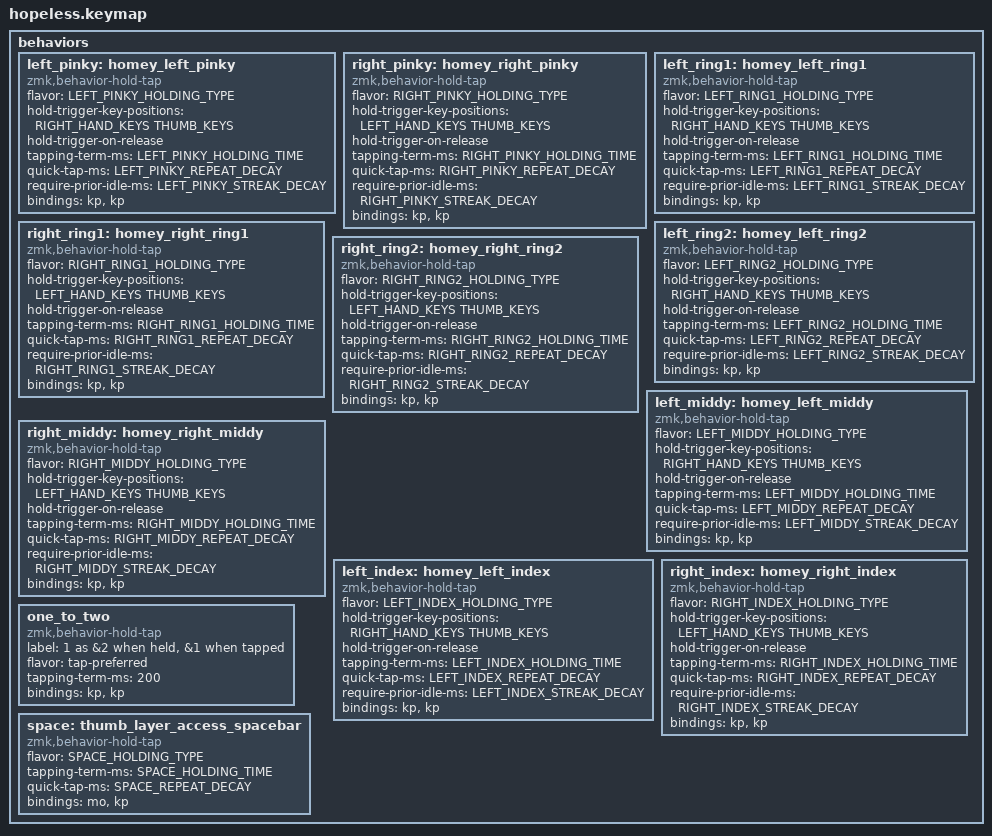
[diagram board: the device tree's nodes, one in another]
// NOTE: Use the `#define` settings below to customize this keymap!
// For example, here are the main optional features you can enable:
#define DIFFICULTY_LEVEL  4 // 0:custom, 1:easy -> 5:hard (see below)
// TIP: Add more setting overrides here instead of editing them below.

//////////////////////////////////////////////////////////////////////////////
//
// Advanced Home Row Mods (HRM) Example based on
// Sunaku's Keymap v35 -- "Glorious Engrammer"
// - https://github.com/sunaku/glove80-keymaps
//
//////////////////////////////////////////////////////////////////////////////

//
// DIFFICULTY_LEVEL specifies your level of expertise with this keymap.
// It's meant to help newcomers gradually work their way up to mastery.
// You can disable this setting by omitting it or assigning a `0` zero.
//
// #define DIFFICULTY_LEVEL 0 // custom (see defaults below)
// #define DIFFICULTY_LEVEL 1 // novice (500ms)
// #define DIFFICULTY_LEVEL 2 // slower (400ms)
// #define DIFFICULTY_LEVEL 3 // normal (300ms)
// #define DIFFICULTY_LEVEL 4 // faster (200ms)
// #define DIFFICULTY_LEVEL 5 // expert (100ms)
//
#if defined(DIFFICULTY_LEVEL) && DIFFICULTY_LEVEL > 0
    #define DIFFICULTY_THRESHOLD ((6-DIFFICULTY_LEVEL)*100)

    #ifndef HOMEY_HOLDING_TIME
        #define HOMEY_HOLDING_TIME DIFFICULTY_THRESHOLD
    #endif

    #ifndef INDEX_HOLDING_TIME
        #define INDEX_HOLDING_TIME DIFFICULTY_THRESHOLD
    #endif
#endif

behaviors {

    //////////////////////////////////////////////////////////////////////////
    //
    // Miryoku layers and home row mods (ported from my QMK endgame)
    // - https://sunaku.github.io/home-row-mods.html#porting-to-zmk
    // - https://github.com/urob/zmk-config#timeless-homerow-mods
    //
    //////////////////////////////////////////////////////////////////////////

    //
    // HOMEY_HOLDING_TYPE defines the flavor of ZMK hold-tap behavior to use
    // for the pinky, ring, and middle fingers (which are assigned to Super,
    // Alt, and Ctrl respectively in the Miryoku system) on home row keys.
    //
    #ifndef HOMEY_HOLDING_TYPE
        #define HOMEY_HOLDING_TYPE "tap-preferred"
    #endif

    //
    // HOMEY_HOLDING_TIME defines how long you need to hold (milliseconds)
    // home row mod keys in order to send their modifiers to the computer
    // (i.e. "register" them) for mod-click mouse usage (e.g. Ctrl-Click).
    //
    #ifndef HOMEY_HOLDING_TIME
        #define HOMEY_HOLDING_TIME 270 // TAPPING_TERM + ALLOW_CROSSOVER_AFTER
    #endif

    //
    // HOMEY_STREAK_DECAY defines how long you need to wait (milliseconds)
    // after typing before you can use home row mods again.  It prevents
    // unintended activation of home row mods when you're actively typing.
    //
    #ifndef HOMEY_STREAK_DECAY
        #define HOMEY_STREAK_DECAY 250
    #endif

    //
    // HOMEY_REPEAT_DECAY defines how much time you have left (milliseconds)
    // after tapping a key to hold it again in order to make it auto-repeat.
    //
    #ifndef HOMEY_REPEAT_DECAY
        #define HOMEY_REPEAT_DECAY 300 // "tap then hold" for key auto-repeat
    #endif

    //
    // INDEX_HOLDING_TYPE defines the flavor of ZMK hold-tap behavior to use
    // for index fingers (which Miryoku assigns to Shift) on home row keys.
    //
    #ifndef INDEX_HOLDING_TYPE
        #define INDEX_HOLDING_TYPE "tap-preferred"
    #endif

    //
    // INDEX_HOLDING_TIME defines how long you need to hold (milliseconds)
    // index finger keys in order to send their modifiers to the computer
    // (i.e. "register" them) for mod-click mouse usage (e.g. Shift-Click).
    //
    #ifndef INDEX_HOLDING_TIME
        #define INDEX_HOLDING_TIME 170
    #endif

    //
    // INDEX_STREAK_DECAY defines how long you need to wait (milliseconds)
    // after typing before you can use home row mods again.  It prevents
    // unintended activation of home row mods when you're actively typing.
    //
    #ifndef INDEX_STREAK_DECAY
        #define INDEX_STREAK_DECAY 150
    #endif

    //
    // INDEX_REPEAT_DECAY defines how much time you have left (milliseconds)
    // after tapping a key to hold it again in order to make it auto-repeat.
    //
    #ifndef INDEX_REPEAT_DECAY
        #define INDEX_REPEAT_DECAY 300 // "tap then hold" for key auto-repeat
    #endif

    //
    // Glove80 key positions index for positional hold-tap
    // - https://discord.com/channels/877392805654306816/937645688244826154/1066713913351221248
    // - https://media.discordapp.net/attachments/937645688244826154/1066713913133121556/image.png
    //
    // |------------------------|------------------------|
    // | LEFT_HAND_KEYS         |        RIGHT_HAND_KEYS |
    // |                        |                        |
    // |  0  1  2  3  4         |          5  6  7  8  9 |
    // | 10 11 12 13 14 15      |      16 17 18 19 20 21 |
    // | 22 23 24 25 26 27      |      28 29 30 31 32 33 |
    // | 34 35 36 37 38 39      |      40 41 42 43 44 45 |
    // | 46 47 48 49 50 51      |      58 59 60 61 62 63 |
    // | 64 65 66 67 68         |         75 76 77 78 79 |
    // |                69 52   |   57 74                |
    // |                 70 53  |  56 73                 |
    // |                  71 54 | 55 72                  |
    // |------------------------|------------------------|
    //
    #define LEFT_HAND_KEYS      \
          0  1  2  3  4         \
         10 11 12 13 14 15      \
         22 23 24 25 26 27      \
         34 35 36 37 38 39      \
         46 47 48 49 50 51      \
         64 65 66 67 68

    #define RIGHT_HAND_KEYS     \
            5  6  7  8  9       \
        16 17 18 19 20 21       \
        28 29 30 31 32 33       \
        40 41 42 43 44 45       \
        58 59 60 61 62 63       \
           75 76 77 78 79

    #define THUMB_KEYS          \
        69 52       57 74       \
            70 53     56 73     \
            71 54   55 72

    //
    // Home row mods with per-finger configuration settings
    //
    #ifndef PINKY_HOLDING_TYPE
        #define PINKY_HOLDING_TYPE HOMEY_HOLDING_TYPE
    #endif
    #ifndef PINKY_HOLDING_TIME
        #define PINKY_HOLDING_TIME HOMEY_HOLDING_TIME
    #endif
    #ifndef PINKY_STREAK_DECAY
        #define PINKY_STREAK_DECAY HOMEY_STREAK_DECAY
    #endif
    #ifndef PINKY_REPEAT_DECAY
        #define PINKY_REPEAT_DECAY HOMEY_REPEAT_DECAY
    #endif
    #ifndef RING1_HOLDING_TYPE
        #define RING1_HOLDING_TYPE HOMEY_HOLDING_TYPE
    #endif
    #ifndef RING1_HOLDING_TIME
        #define RING1_HOLDING_TIME HOMEY_HOLDING_TIME
    #endif
    #ifndef RING1_STREAK_DECAY
        #define RING1_STREAK_DECAY HOMEY_STREAK_DECAY
    #endif
    #ifndef RING1_REPEAT_DECAY
        #define RING1_REPEAT_DECAY HOMEY_REPEAT_DECAY
    #endif
    #ifndef RING2_HOLDING_TYPE
        #define RING2_HOLDING_TYPE HOMEY_HOLDING_TYPE
    #endif
    #ifndef RING2_HOLDING_TIME
        #define RING2_HOLDING_TIME HOMEY_HOLDING_TIME
    #endif
    #ifndef RING2_STREAK_DECAY
        #define RING2_STREAK_DECAY HOMEY_STREAK_DECAY
    #endif
    #ifndef RING2_REPEAT_DECAY
        #define RING2_REPEAT_DECAY HOMEY_REPEAT_DECAY
    #endif
    #ifndef MIDDY_HOLDING_TYPE
        #define MIDDY_HOLDING_TYPE HOMEY_HOLDING_TYPE
    #endif
    #ifndef MIDDY_HOLDING_TIME
        #define MIDDY_HOLDING_TIME HOMEY_HOLDING_TIME
    #endif
    #ifndef MIDDY_STREAK_DECAY
        #define MIDDY_STREAK_DECAY HOMEY_STREAK_DECAY
    #endif
    #ifndef MIDDY_REPEAT_DECAY
        #define MIDDY_REPEAT_DECAY HOMEY_REPEAT_DECAY
    #endif
    #ifndef INDEX_HOLDING_TYPE
        #define INDEX_HOLDING_TYPE HOMEY_HOLDING_TYPE
    #endif
    #ifndef INDEX_HOLDING_TIME
        #define INDEX_HOLDING_TIME HOMEY_HOLDING_TIME
    #endif
    #ifndef INDEX_STREAK_DECAY
        #define INDEX_STREAK_DECAY HOMEY_STREAK_DECAY
    #endif
    #ifndef INDEX_REPEAT_DECAY
        #define INDEX_REPEAT_DECAY HOMEY_REPEAT_DECAY
    #endif
    #ifndef LEFT_PINKY_HOLDING_TYPE
        #define LEFT_PINKY_HOLDING_TYPE PINKY_HOLDING_TYPE
    #endif
    #ifndef LEFT_PINKY_HOLDING_TIME
        #define LEFT_PINKY_HOLDING_TIME PINKY_HOLDING_TIME
    #endif
    #ifndef LEFT_PINKY_STREAK_DECAY
        #define LEFT_PINKY_STREAK_DECAY PINKY_STREAK_DECAY
    #endif
    #ifndef LEFT_PINKY_REPEAT_DECAY
        #define LEFT_PINKY_REPEAT_DECAY PINKY_REPEAT_DECAY
    #endif

    left_pinky: homey_left_pinky {
        compatible = "zmk,behavior-hold-tap";
        flavor = LEFT_PINKY_HOLDING_TYPE;
        hold-trigger-key-positions = <RIGHT_HAND_KEYS THUMB_KEYS>;
        hold-trigger-on-release; // wait for other home row mods
        tapping-term-ms = <LEFT_PINKY_HOLDING_TIME>;
        quick-tap-ms = <LEFT_PINKY_REPEAT_DECAY>;
        require-prior-idle-ms = <LEFT_PINKY_STREAK_DECAY>;
        #binding-cells = <2>;
        bindings = <&kp>, <&kp>;
    };

    #ifndef RIGHT_PINKY_HOLDING_TYPE
        #define RIGHT_PINKY_HOLDING_TYPE PINKY_HOLDING_TYPE
    #endif
    #ifndef RIGHT_PINKY_HOLDING_TIME
        #define RIGHT_PINKY_HOLDING_TIME PINKY_HOLDING_TIME
    #endif
    #ifndef RIGHT_PINKY_STREAK_DECAY
        #define RIGHT_PINKY_STREAK_DECAY PINKY_STREAK_DECAY
    #endif
    #ifndef RIGHT_PINKY_REPEAT_DECAY
        #define RIGHT_PINKY_REPEAT_DECAY PINKY_REPEAT_DECAY
    #endif

    right_pinky: homey_right_pinky {
        compatible = "zmk,behavior-hold-tap";
        flavor = RIGHT_PINKY_HOLDING_TYPE;
        hold-trigger-key-positions = <LEFT_HAND_KEYS THUMB_KEYS>;
        hold-trigger-on-release; // wait for other home row mods
        tapping-term-ms = <RIGHT_PINKY_HOLDING_TIME>;
        quick-tap-ms = <RIGHT_PINKY_REPEAT_DECAY>;
        require-prior-idle-ms = <RIGHT_PINKY_STREAK_DECAY>;
        #binding-cells = <2>;
        bindings = <&kp>, <&kp>;
    };

    #ifndef LEFT_RING1_HOLDING_TYPE
        #define LEFT_RING1_HOLDING_TYPE RING1_HOLDING_TYPE
    #endif
    #ifndef LEFT_RING1_HOLDING_TIME
        #define LEFT_RING1_HOLDING_TIME RING1_HOLDING_TIME
    #endif
    #ifndef LEFT_RING1_STREAK_DECAY
        #define LEFT_RING1_STREAK_DECAY RING1_STREAK_DECAY
    #endif
    #ifndef LEFT_RING1_REPEAT_DECAY
        #define LEFT_RING1_REPEAT_DECAY RING1_REPEAT_DECAY
    #endif

    left_ring1: homey_left_ring1 {
        compatible = "zmk,behavior-hold-tap";
        flavor = LEFT_RING1_HOLDING_TYPE;
        hold-trigger-key-positions = <RIGHT_HAND_KEYS THUMB_KEYS>;
        hold-trigger-on-release; // wait for other home row mods
        tapping-term-ms = <LEFT_RING1_HOLDING_TIME>;
        quick-tap-ms = <LEFT_RING1_REPEAT_DECAY>;
        require-prior-idle-ms = <LEFT_RING1_STREAK_DECAY>;
        #binding-cells = <2>;
        bindings = <&kp>, <&kp>;
    };

    #ifndef RIGHT_RING1_HOLDING_TYPE
        #define RIGHT_RING1_HOLDING_TYPE RING1_HOLDING_TYPE
    #endif
    #ifndef RIGHT_RING1_HOLDING_TIME
        #define RIGHT_RING1_HOLDING_TIME RING1_HOLDING_TIME
    #endif
    #ifndef RIGHT_RING1_STREAK_DECAY
        #define RIGHT_RING1_STREAK_DECAY RING1_STREAK_DECAY
    #endif
    #ifndef RIGHT_RING1_REPEAT_DECAY
        #define RIGHT_RING1_REPEAT_DECAY RING1_REPEAT_DECAY
    #endif

    right_ring1: homey_right_ring1 {
        compatible = "zmk,behavior-hold-tap";
        flavor = RIGHT_RING1_HOLDING_TYPE;
        hold-trigger-key-positions = <LEFT_HAND_KEYS THUMB_KEYS>;
        hold-trigger-on-release; // wait for other home row mods
        tapping-term-ms = <RIGHT_RING1_HOLDING_TIME>;
        quick-tap-ms = <RIGHT_RING1_REPEAT_DECAY>;
        require-prior-idle-ms = <RIGHT_RING1_STREAK_DECAY>;
        #binding-cells = <2>;
        bindings = <&kp>, <&kp>;
    };

    #ifndef LEFT_RING2_HOLDING_TYPE
        #define LEFT_RING2_HOLDING_TYPE RING2_HOLDING_TYPE
    #endif
    #ifndef LEFT_RING2_HOLDING_TIME
        #define LEFT_RING2_HOLDING_TIME RING2_HOLDING_TIME
    #endif
    #ifndef LEFT_RING2_STREAK_DECAY
        #define LEFT_RING2_STREAK_DECAY RING2_STREAK_DECAY
    #endif
    #ifndef LEFT_RING2_REPEAT_DECAY
        #define LEFT_RING2_REPEAT_DECAY RING2_REPEAT_DECAY
    #endif

    left_ring2: homey_left_ring2 {
        compatible = "zmk,behavior-hold-tap";
        flavor = LEFT_RING2_HOLDING_TYPE;
        hold-trigger-key-positions = <RIGHT_HAND_KEYS THUMB_KEYS>;
        hold-trigger-on-release; // wait for other home row mods
        tapping-term-ms = <LEFT_RING2_HOLDING_TIME>;
        quick-tap-ms = <LEFT_RING2_REPEAT_DECAY>;
        require-prior-idle-ms = <LEFT_RING2_STREAK_DECAY>;
        #binding-cells = <2>;
        bindings = <&kp>, <&kp>;
    };

    #ifndef RIGHT_RING2_HOLDING_TYPE
        #define RIGHT_RING2_HOLDING_TYPE RING2_HOLDING_TYPE
    #endif
    #ifndef RIGHT_RING2_HOLDING_TIME
        #define RIGHT_RING2_HOLDING_TIME RING2_HOLDING_TIME
    #endif
    #ifndef RIGHT_RING2_STREAK_DECAY
        #define RIGHT_RING2_STREAK_DECAY RING2_STREAK_DECAY
    #endif
    #ifndef RIGHT_RING2_REPEAT_DECAY
        #define RIGHT_RING2_REPEAT_DECAY RING2_REPEAT_DECAY
    #endif

    right_ring2: homey_right_ring2 {
        compatible = "zmk,behavior-hold-tap";
        flavor = RIGHT_RING2_HOLDING_TYPE;
        hold-trigger-key-positions = <LEFT_HAND_KEYS THUMB_KEYS>;
        hold-trigger-on-release; // wait for other home row mods
        tapping-term-ms = <RIGHT_RING2_HOLDING_TIME>;
        quick-tap-ms = <RIGHT_RING2_REPEAT_DECAY>;
        require-prior-idle-ms = <RIGHT_RING2_STREAK_DECAY>;
        #binding-cells = <2>;
        bindings = <&kp>, <&kp>;
    };

    #ifndef LEFT_MIDDY_HOLDING_TYPE
        #define LEFT_MIDDY_HOLDING_TYPE MIDDY_HOLDING_TYPE
    #endif
    #ifndef LEFT_MIDDY_HOLDING_TIME
        #define LEFT_MIDDY_HOLDING_TIME MIDDY_HOLDING_TIME
    #endif
    #ifndef LEFT_MIDDY_STREAK_DECAY
        #define LEFT_MIDDY_STREAK_DECAY MIDDY_STREAK_DECAY
    #endif
    #ifndef LEFT_MIDDY_REPEAT_DECAY
        #define LEFT_MIDDY_REPEAT_DECAY MIDDY_REPEAT_DECAY
    #endif

    left_middy: homey_left_middy {
        compatible = "zmk,behavior-hold-tap";
        flavor = LEFT_MIDDY_HOLDING_TYPE;
        hold-trigger-key-positions = <RIGHT_HAND_KEYS THUMB_KEYS>;
        hold-trigger-on-release; // wait for other home row mods
        tapping-term-ms = <LEFT_MIDDY_HOLDING_TIME>;
        quick-tap-ms = <LEFT_MIDDY_REPEAT_DECAY>;
        require-prior-idle-ms = <LEFT_MIDDY_STREAK_DECAY>;
        #binding-cells = <2>;
        bindings = <&kp>, <&kp>;
    };

    #ifndef RIGHT_MIDDY_HOLDING_TYPE
        #define RIGHT_MIDDY_HOLDING_TYPE MIDDY_HOLDING_TYPE
    #endif
    #ifndef RIGHT_MIDDY_HOLDING_TIME
        #define RIGHT_MIDDY_HOLDING_TIME MIDDY_HOLDING_TIME
    #endif
    #ifndef RIGHT_MIDDY_STREAK_DECAY
        #define RIGHT_MIDDY_STREAK_DECAY MIDDY_STREAK_DECAY
    #endif
    #ifndef RIGHT_MIDDY_REPEAT_DECAY
        #define RIGHT_MIDDY_REPEAT_DECAY MIDDY_REPEAT_DECAY
    #endif

    right_middy: homey_right_middy {
        compatible = "zmk,behavior-hold-tap";
        flavor = RIGHT_MIDDY_HOLDING_TYPE;
        hold-trigger-key-positions = <LEFT_HAND_KEYS THUMB_KEYS>;
        hold-trigger-on-release; // wait for other home row mods
        tapping-term-ms = <RIGHT_MIDDY_HOLDING_TIME>;
        quick-tap-ms = <RIGHT_MIDDY_REPEAT_DECAY>;
        require-prior-idle-ms = <RIGHT_MIDDY_STREAK_DECAY>;
        #binding-cells = <2>;
        bindings = <&kp>, <&kp>;
    };

    #ifndef LEFT_INDEX_HOLDING_TYPE
        #define LEFT_INDEX_HOLDING_TYPE INDEX_HOLDING_TYPE
    #endif
    #ifndef LEFT_INDEX_HOLDING_TIME
        #define LEFT_INDEX_HOLDING_TIME INDEX_HOLDING_TIME
    #endif
    #ifndef LEFT_INDEX_STREAK_DECAY
        #define LEFT_INDEX_STREAK_DECAY INDEX_STREAK_DECAY
    #endif
    #ifndef LEFT_INDEX_REPEAT_DECAY
        #define LEFT_INDEX_REPEAT_DECAY INDEX_REPEAT_DECAY
    #endif

    left_index: homey_left_index {
        compatible = "zmk,behavior-hold-tap";
        flavor = LEFT_INDEX_HOLDING_TYPE;
        hold-trigger-key-positions = <RIGHT_HAND_KEYS THUMB_KEYS>;
        hold-trigger-on-release; // wait for other home row mods
        tapping-term-ms = <LEFT_INDEX_HOLDING_TIME>;
        quick-tap-ms = <LEFT_INDEX_REPEAT_DECAY>;
        require-prior-idle-ms = <LEFT_INDEX_STREAK_DECAY>;
        #binding-cells = <2>;
        bindings = <&kp>, <&kp>;
    };

    #ifndef RIGHT_INDEX_HOLDING_TYPE
        #define RIGHT_INDEX_HOLDING_TYPE INDEX_HOLDING_TYPE
    #endif
    #ifndef RIGHT_INDEX_HOLDING_TIME
        #define RIGHT_INDEX_HOLDING_TIME INDEX_HOLDING_TIME
    #endif
    #ifndef RIGHT_INDEX_STREAK_DECAY
        #define RIGHT_INDEX_STREAK_DECAY INDEX_STREAK_DECAY
    #endif
    #ifndef RIGHT_INDEX_REPEAT_DECAY
        #define RIGHT_INDEX_REPEAT_DECAY INDEX_REPEAT_DECAY
    #endif

    right_index: homey_right_index {
        compatible = "zmk,behavior-hold-tap";
        flavor = RIGHT_INDEX_HOLDING_TYPE;
        hold-trigger-key-positions = <LEFT_HAND_KEYS THUMB_KEYS>;
        hold-trigger-on-release; // wait for other home row mods
        tapping-term-ms = <RIGHT_INDEX_HOLDING_TIME>;
        quick-tap-ms = <RIGHT_INDEX_REPEAT_DECAY>;
        require-prior-idle-ms = <RIGHT_INDEX_STREAK_DECAY>;
        #binding-cells = <2>;
        bindings = <&kp>, <&kp>;
    };

    // 1 as &2 when held, &1 when tapped

    one_to_two: one_to_two {
        compatible = "zmk,behavior-hold-tap";
        label = "1 as &2 when held, &1 when tapped";
        flavor = "tap-preferred";
        tapping-term-ms = <200>;
        #binding-cells = <2>;
        bindings = <&kp>, <&kp>;
    };
    // Symbol layer

    //
    // SPACE_HOLDING_TYPE defines the flavor of ZMK hold-tap behavior to use
    // for spacebar (assigned to the right thumb's home position by default).
    //
    // NOTE: The "balanced" flavor of ZMK hold-tap provides instant modifier
    // activation for the symbol layer (if the tapped symbol key is released
    // while the thumb layer key is still held down) for quicker programming.
    //
    #ifndef SPACE_HOLDING_TYPE
        #define SPACE_HOLDING_TYPE "balanced"
    #endif

    //
    // SPACE_HOLDING_TIME defines how long you need to hold (milliseconds)
    // the space thumb key to activate.  Shorter holds are treated as taps.
    //
    #ifndef SPACE_HOLDING_TIME
        #define SPACE_HOLDING_TIME 200
    #endif

    //
    // SPACE_REPEAT_DECAY defines how much time you have left (milliseconds)
    // after tapping a key to hold it again in order to make it auto-repeat.
    //
    #ifndef SPACE_REPEAT_DECAY
        #define SPACE_REPEAT_DECAY 150
    #endif

    space: thumb_layer_access_spacebar {
        compatible = "zmk,behavior-hold-tap";
        flavor = SPACE_HOLDING_TYPE;
        tapping-term-ms = <SPACE_HOLDING_TIME>;
        quick-tap-ms = <SPACE_REPEAT_DECAY>; // enable repeat
        #binding-cells = <2>;
        bindings = <&mo>, <&kp>;
    };
};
